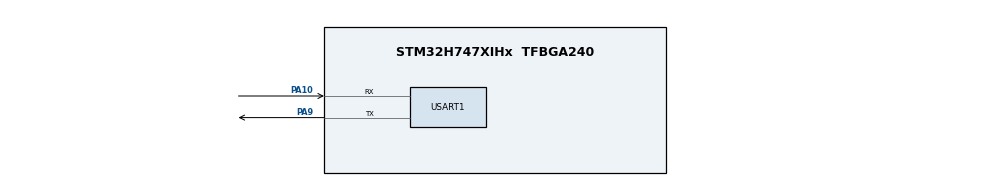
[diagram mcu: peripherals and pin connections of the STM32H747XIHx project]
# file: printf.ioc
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CortexM4.IPs=BDMA,DMA,FATFS_M4\:I,FREERTOS_M4\:I,IWDG2\:I,MDMA,NVIC2\:I,RCC,USB_DEVICE_M4\:I,USB_HOST_M4\:I,WWDG2\:I,DEBUG,PDM2PCM_M4\:I,PWR,RESMGR_UTILITY,SYS_M4\:I,CORTEX_M4\:I,OPENAMP_M4\:I,VREFBUF,GPIO
CortexM7.IPs=BDMA\:I,DMA\:I,FATFS_M7\:I,FREERTOS_M7\:I,IWDG1\:I,MDMA\:I,NVIC1\:I,RCC\:I,USB_DEVICE_M7\:I,USB_HOST_M7\:I,WWDG1\:I,CORTEX_M7\:I,DEBUG\:I,PDM2PCM_M7\:I,PWR\:I,RESMGR_UTILITY\:I,SYS\:I,OPENAMP_M7\:I,VREFBUF\:I,GPIO\:I,USART1\:I
Mcu.Family=STM32H7
Mcu.Name=STM32H747XIHx
Mcu.Package=TFBGA240
NVIC1.PriorityGroup=NVIC_PRIORITYGROUP_4
NVIC2.PriorityGroup=NVIC_PRIORITYGROUP_4
PA10.Mode=Asynchronous
PA10.PinAttribute=CortexM7
PA10.Signal=USART1_RX
PA9.Mode=Asynchronous
PA9.PinAttribute=CortexM7
PA9.Signal=USART1_TX
PH0-OSC_IN\ (PH0).Mode=HSE-External-Oscillator
PH0-OSC_IN\ (PH0).PinAttribute=Free
PH0-OSC_IN\ (PH0).Signal=RCC_OSC_IN
PH1-OSC_OUT\ (PH1).Mode=HSE-External-Oscillator
PH1-OSC_OUT\ (PH1).PinAttribute=Free
PH1-OSC_OUT\ (PH1).Signal=RCC_OSC_OUT
ProjectManager.HeapSize=M4-0x200,M7-0x200
ProjectManager.StackSize=M4-0x400,M7-0x400
ProjectManager.TargetToolchain=STM32CubeIDE
RCC.ADCFreq_Value=75000000
RCC.APB1Freq_Value=64000000
RCC.APB2Freq_Value=64000000
RCC.APB3Freq_Value=64000000
RCC.APB4Freq_Value=64000000
RCC.CortexFreq_Value=64000000
RCC.DIVM2=4
RCC.DIVN2=9
RCC.HCLKFreq_Value=64000000
RCC.PLL2FRACN=3072
RCC.PWR_Regulator_Voltage_Scale=PWR_REGULATOR_VOLTAGE_SCALE1
RCC.SYSCLKFreq_VALUE=64000000
RCC.SupplySource=PWR_DIRECT_SMPS_SUPPLY
RCC.USBFreq_Value=129000000
USART1.VirtualMode-Asynchronous=VM_ASYNC
VP_SYS_M4_VS_Systick.Mode=SysTick
board=STM32H747I-DISCO

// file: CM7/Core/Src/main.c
/* USER CODE BEGIN Header */
/**
  ******************************************************************************
  * @file           : main.c
  * @brief          : Main program body
  ******************************************************************************
  * @attention
  *
  * Copyright (c) 2023 STMicroelectronics.
  * All rights reserved.
  *
  * This software is licensed under terms that can be found in the LICENSE file
  * in the root directory of this software component.
  * If no LICENSE file comes with this software, it is provided AS-IS.
  *
  ******************************************************************************
  */
/* USER CODE END Header */
#include "main.h"
#include "usart.h"
#include "gpio.h"

/* USER CODE BEGIN Includes */
#include <stdio.h>
/* USER CODE END Includes */

/* USER CODE BEGIN PD */

#ifndef HSEM_ID_0
#define HSEM_ID_0 (0U) /* HW semaphore 0*/
#endif

/* USER CODE END PD */

/* USER CODE BEGIN PM */
int _write(int fd, char * ptr, int len) {
	HAL_UART_Transmit(&huart1, (uint8_t *) ptr, len, HAL_MAX_DELAY);
	return len;
}
/* USER CODE END PM */

void SystemClock_Config(void);

int main(void)
{
/* USER CODE BEGIN Boot_Mode_Sequence_0 */
  int32_t timeout;
/* USER CODE END Boot_Mode_Sequence_0 */

/* USER CODE BEGIN Boot_Mode_Sequence_1 */
  /* Wait until CPU2 boots and enters in stop mode or timeout*/
  timeout = 0xFFFF;
  while((__HAL_RCC_GET_FLAG(RCC_FLAG_D2CKRDY) != RESET) && (timeout-- > 0));
  if ( timeout < 0 )
  {
  Error_Handler();
  }
/* USER CODE END Boot_Mode_Sequence_1 */
  /* MCU Configuration--------------------------------------------------------*/

  /* Reset of all peripherals, Initializes the Flash interface and the Systick. */
  HAL_Init();

  /* Configure the system clock */
  SystemClock_Config();
/* USER CODE BEGIN Boot_Mode_Sequence_2 */
/* When system initialization is finished, Cortex-M7 will release Cortex-M4 by means of
HSEM notification */
/*HW semaphore Clock enable*/
__HAL_RCC_HSEM_CLK_ENABLE();
/*Take HSEM */
HAL_HSEM_FastTake(HSEM_ID_0);
/*Release HSEM in order to notify the CPU2(CM4)*/
HAL_HSEM_Release(HSEM_ID_0,0);
/* wait until CPU2 wakes up from stop mode */
timeout = 0xFFFF;
while((__HAL_RCC_GET_FLAG(RCC_FLAG_D2CKRDY) == RESET) && (timeout-- > 0));
if ( timeout < 0 )
{
Error_Handler();
}
/* USER CODE END Boot_Mode_Sequence_2 */

  /* Initialize all configured peripherals */
  MX_GPIO_Init();
  MX_USART1_UART_Init();

  /* Infinite loop */
  /* USER CODE BEGIN WHILE */
  int count = 0;
  float fcount = 0.0;
  while (1)
  {
	  // To printf the floating number, you set option in
	  // Project -> Properties -> C/C++ Build -> Settings -> Tool Settings -> MCU GCC Linker -> Miscellaneous
	  // -u_printf_float
	  // Refer to https://swiftcam.tistory.com/144
	  printf("Count: %d\tFloat Count: %f\r\n", count, fcount);
	  count++;
	  fcount += 0.5;
	  HAL_Delay(1000);
    /* USER CODE END WHILE */

  }
}

void SystemClock_Config(void)
{
  RCC_OscInitTypeDef RCC_OscInitStruct = {0};
  RCC_ClkInitTypeDef RCC_ClkInitStruct = {0};

  /** Supply configuration update enable
  */
  HAL_PWREx_ConfigSupply(PWR_DIRECT_SMPS_SUPPLY);

  /** Configure the main internal regulator output voltage
  */
  __HAL_PWR_VOLTAGESCALING_CONFIG(PWR_REGULATOR_VOLTAGE_SCALE1);

  while(!__HAL_PWR_GET_FLAG(PWR_FLAG_VOSRDY)) {}

  /** Initializes the RCC Oscillators according to the specified parameters
  * in the RCC_OscInitTypeDef structure.
  */
  RCC_OscInitStruct.OscillatorType = RCC_OSCILLATORTYPE_HSI;
  RCC_OscInitStruct.HSIState = RCC_HSI_DIV1;
  RCC_OscInitStruct.HSICalibrationValue = RCC_HSICALIBRATION_DEFAULT;
  RCC_OscInitStruct.PLL.PLLState = RCC_PLL_NONE;
  if (HAL_RCC_OscConfig(&RCC_OscInitStruct) != HAL_OK)
  {
    Error_Handler();
  }

  /** Initializes the CPU, AHB and APB buses clocks
  */
  RCC_ClkInitStruct.ClockType = RCC_CLOCKTYPE_HCLK|RCC_CLOCKTYPE_SYSCLK
                              |RCC_CLOCKTYPE_PCLK1|RCC_CLOCKTYPE_PCLK2
                              |RCC_CLOCKTYPE_D3PCLK1|RCC_CLOCKTYPE_D1PCLK1;
  RCC_ClkInitStruct.SYSCLKSource = RCC_SYSCLKSOURCE_HSI;
  RCC_ClkInitStruct.SYSCLKDivider = RCC_SYSCLK_DIV1;
  RCC_ClkInitStruct.AHBCLKDivider = RCC_HCLK_DIV1;
  RCC_ClkInitStruct.APB3CLKDivider = RCC_APB3_DIV1;
  RCC_ClkInitStruct.APB1CLKDivider = RCC_APB1_DIV1;
  RCC_ClkInitStruct.APB2CLKDivider = RCC_APB2_DIV1;
  RCC_ClkInitStruct.APB4CLKDivider = RCC_APB4_DIV1;

  if (HAL_RCC_ClockConfig(&RCC_ClkInitStruct, FLASH_LATENCY_0) != HAL_OK)
  {
    Error_Handler();
  }
}

void Error_Handler(void)
{
  __disable_irq();
  while (1)
  {
  }
}
